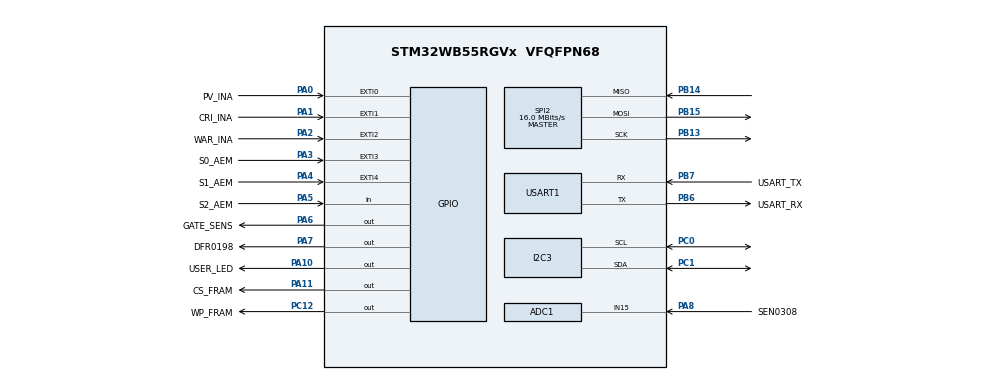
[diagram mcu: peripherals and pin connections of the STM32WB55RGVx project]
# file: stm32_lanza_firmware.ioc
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ADC1.Channel-0\#ChannelRegularConversion=ADC_CHANNEL_15
ADC1.NbrOfConversionFlag=1
ADC1.OffsetNumber-0\#ChannelRegularConversion=ADC_OFFSET_NONE
ADC1.Rank-0\#ChannelRegularConversion=1
ADC1.SamplingTime-0\#ChannelRegularConversion=ADC_SAMPLETIME_47CYCLES_5
ADC1.master=1
I2C3.Timing=0x00B07CB4
Mcu.Family=STM32WB
Mcu.Name=STM32WB55RGVx
Mcu.Package=VFQFPN68
NVIC.EXTI0_IRQn=true\:0\:0\:false\:false\:true\:true\:true\:true
NVIC.EXTI1_IRQn=true\:0\:0\:false\:false\:true\:true\:true\:true
NVIC.EXTI2_IRQn=true\:0\:0\:false\:false\:true\:true\:true\:true
NVIC.EXTI3_IRQn=true\:0\:0\:false\:false\:true\:true\:true\:true
NVIC.EXTI4_IRQn=true\:0\:0\:false\:false\:true\:true\:true\:true
NVIC.PriorityGroup=NVIC_PRIORITYGROUP_4
NVIC.RTC_WKUP_IRQn=true\:0\:0\:false\:false\:true\:true\:true\:true
NVIC.USART1_IRQn=true\:0\:0\:false\:false\:true\:true\:true\:true
OSC_IN.GPIO_Label=RCC_OSC_IN
OSC_IN.Mode=HSE-External-Oscillator
OSC_IN.Signal=RCC_OSC_IN
OSC_OUT.GPIO_Label=RCC_OSC_OUT
OSC_OUT.Mode=HSE-External-Oscillator
OSC_OUT.Signal=RCC_OSC_OUT
PA0.GPIO_Label=PV_INA
PA0.Signal=GPXTI0
PA1.GPIO_Label=CRI_INA
PA1.Signal=GPXTI1
PA10.GPIO_Label=USER_LED
PA10.Signal=GPIO_Output
PA11.GPIO_Label=CS_FRAM
PA11.Signal=GPIO_Output
PA13.Mode=Serial_Wire
PA13.Signal=SYS_JTMS-SWDIO
PA14.Mode=Serial_Wire
PA14.Signal=SYS_JTCK-SWCLK
PA2.GPIO_Label=WAR_INA
PA2.Signal=GPXTI2
PA3.GPIO_Label=S0_AEM
PA3.GPIO_ModeDefaultEXTI=GPIO_MODE_IT_RISING_FALLING
PA3.Signal=GPXTI3
PA4.GPIO_Label=S1_AEM
PA4.Signal=GPXTI4
PA5.GPIO_Label=S2_AEM
PA5.Signal=GPIO_Input
PA6.GPIO_Label=GATE_SENS
PA6.Signal=GPIO_Output
PA7.GPIO_Label=DFR0198
PA7.GPIO_ModeDefaultOutputPP=GPIO_MODE_OUTPUT_OD
PA7.GPIO_PuPd=GPIO_PULLUP
PA7.PinState=GPIO_PIN_SET
PA7.Signal=GPIO_Output
PA8.GPIO_Label=SEN0308
PA8.Signal=ADCx_IN15
PB13.Mode=Full_Duplex_Master
PB13.Signal=SPI2_SCK
PB14.Mode=Full_Duplex_Master
PB14.Signal=SPI2_MISO
PB15.Mode=Full_Duplex_Master
PB15.Signal=SPI2_MOSI
PB6.GPIO_Label=USART_RX
PB6.Mode=Asynchronous
PB6.Signal=USART1_TX
PB7.GPIO_Label=USART_TX
PB7.Mode=Asynchronous
PB7.Signal=USART1_RX
PC0.GPIO_Pu=GPIO_PULLUP
PC0.Mode=I2C
PC0.Signal=I2C3_SCL
PC1.GPIO_Pu=GPIO_PULLUP
PC1.Mode=I2C
PC1.Signal=I2C3_SDA
PC12.GPIO_Label=WP_FRAM
PC12.Signal=GPIO_Output
PC14-OSC32_IN.Mode=LSE-External-Oscillator
PC14-OSC32_IN.Signal=RCC_OSC32_IN
PC15-OSC32_OUT.Mode=LSE-External-Oscillator
PC15-OSC32_OUT.Signal=RCC_OSC32_OUT
ProjectManager.HeapSize=0x200
ProjectManager.StackSize=0x400
ProjectManager.TargetToolchain=STM32CubeIDE
RCC.ADCFreq_Value=64000000
RCC.AHBFreq_Value=32000000
RCC.APB1Freq_Value=32000000
RCC.APB1TimFreq_Value=32000000
RCC.APB2Freq_Value=32000000
RCC.APB2TimFreq_Value=32000000
RCC.APB3Freq_Value=16000000
RCC.CortexFreq_Value=32000000
RCC.HCLKFreq_Value=32000000
RCC.HSE_VALUE=32000000
RCC.HSI48_VALUE=48000000
RCC.HSI_VALUE=16000000
RCC.MSIClockRange=RCC_MSIRANGE_10
RCC.PLLM=RCC_PLLM_DIV2
RCC.RTCClockSelection=RCC_RTCCLKSOURCE_LSE
RCC.SMPSCLockSelection=RCC_SMPSCLKSOURCE_HSI
RCC.SMPSCLockSelectionVirtual=RCC_SMPSCLKSOURCE_HSI
RCC.SMPSCLockSelectionVirtualVirtual=RCC_SMPSCLKSOURCE_HSI
RCC.SMPSDivider=1
RCC.SYSCLKFreq_VALUE=32000000
RCC.USBFreq_Value=64000000
RCC.VCOOutputFreq_Value=128000000
RTC.WakeUpClock-WakeUp=RTC_WAKEUPCLOCK_CK_SPRE_16BITS
RTC.WakeUpCounter-WakeUp=1200
SH.ADCx_IN15.0=ADC1_IN15,IN15-Single-Ended
SPI2.BaudRatePrescaler=SPI_BAUDRATEPRESCALER_2
SPI2.CalculateBaudRate=16.0 MBits/s
SPI2.DataSize=SPI_DATASIZE_8BIT
SPI2.Direction=SPI_DIRECTION_2LINES
SPI2.Mode=SPI_MODE_MASTER
SPI2.VirtualType=VM_MASTER
USART1.AutoBaudRateEnableParam=UART_ADVFEATURE_AUTOBAUDRATE_DISABLE
USART1.VirtualMode-Asynchronous=VM_ASYNC
VP_MEMORYMAP_VS_MEMORYMAP.Mode=CurAppReg
VP_RTC_VS_RTC_Activate.Mode=RTC_Enabled
VP_RTC_VS_RTC_Calendar.Mode=RTC_Calendar
VP_RTC_VS_RTC_WakeUp_intern.Mode=WakeUp
board=NUCLEO-WB55RG

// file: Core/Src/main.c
/* USER CODE BEGIN Header */
/**
  ******************************************************************************
  * @file           : main.c
  * @brief          : Main program body
  ******************************************************************************
  * @attention
  *
  * Copyright (c) 2025 STMicroelectronics.
  * All rights reserved.
  *
  * This software is licensed under terms that can be found in the LICENSE file
  * in the root directory of this software component.
  * If no LICENSE file comes with this software, it is provided AS-IS.
  *
  ******************************************************************************
  */
/* USER CODE END Header */
#include "main.h"

/* USER CODE BEGIN Includes */
#include "app.h"
/* USER CODE END Includes */

ADC_HandleTypeDef hadc1;

I2C_HandleTypeDef hi2c3;

RTC_HandleTypeDef hrtc;

SPI_HandleTypeDef hspi2;

UART_HandleTypeDef huart1;

void SystemClock_Config(void);
void PeriphCommonClock_Config(void);
static void MX_GPIO_Init(void);
static void MX_USART1_UART_Init(void);
static void MX_RTC_Init(void);
static void MX_ADC1_Init(void);
static void MX_I2C3_Init(void);
static void MX_SPI2_Init(void);
/* USER CODE BEGIN PFP */
void ADC1_Init() {
	HAL_ADC_DeInit(&hadc1);
	HAL_ADC_Init(&hadc1);

	MX_ADC1_Init();
}
/* USER CODE END PFP */

/* USER CODE BEGIN 0 */

// Overwritten function to allow printf() via UART
int _write(int file, char *ptr, int len) {
    HAL_UART_Transmit(&huart1, (uint8_t*)ptr, len, HAL_MAX_DELAY);
    return len;
}
/* USER CODE END 0 */

int main(void)
{

  /* MCU Configuration--------------------------------------------------------*/

  /* Reset of all peripherals, Initializes the Flash interface and the Systick. */
  HAL_Init();

  /* Configure the system clock */
  SystemClock_Config();

  /* Configure the peripherals common clocks */
  PeriphCommonClock_Config();

  /* Initialize all configured peripherals */
  MX_GPIO_Init();
  MX_USART1_UART_Init();
  MX_RTC_Init();
  MX_ADC1_Init();
  MX_I2C3_Init();
  MX_SPI2_Init();
  /* USER CODE BEGIN 2 */
  setup();
  /* USER CODE END 2 */

  /* Infinite loop */
  while (1)
  {

    /* USER CODE BEGIN 3 */
	  loop();
  }
  /* USER CODE END 3 */
}

void SystemClock_Config(void)
{
  RCC_OscInitTypeDef RCC_OscInitStruct = {0};
  RCC_ClkInitTypeDef RCC_ClkInitStruct = {0};

  /** Macro to configure the PLL multiplication factor
  */
  __HAL_RCC_PLL_PLLM_CONFIG(RCC_PLLM_DIV2);

  /** Macro to configure the PLL clock source
  */
  __HAL_RCC_PLL_PLLSOURCE_CONFIG(RCC_PLLSOURCE_MSI);

  /** Configure LSE Drive Capability
  */
  HAL_PWR_EnableBkUpAccess();
  __HAL_RCC_LSEDRIVE_CONFIG(RCC_LSEDRIVE_MEDIUMHIGH);

  /** Configure the main internal regulator output voltage
  */
  __HAL_PWR_VOLTAGESCALING_CONFIG(PWR_REGULATOR_VOLTAGE_SCALE1);

  /** Initializes the RCC Oscillators according to the specified parameters
  * in the RCC_OscInitTypeDef structure.
  */
  RCC_OscInitStruct.OscillatorType = RCC_OSCILLATORTYPE_HSI|RCC_OSCILLATORTYPE_HSE
                              |RCC_OSCILLATORTYPE_LSE|RCC_OSCILLATORTYPE_MSI;
  RCC_OscInitStruct.HSEState = RCC_HSE_ON;
  RCC_OscInitStruct.LSEState = RCC_LSE_ON;
  RCC_OscInitStruct.HSIState = RCC_HSI_ON;
  RCC_OscInitStruct.MSIState = RCC_MSI_ON;
  RCC_OscInitStruct.HSICalibrationValue = RCC_HSICALIBRATION_DEFAULT;
  RCC_OscInitStruct.MSICalibrationValue = RCC_MSICALIBRATION_DEFAULT;
  RCC_OscInitStruct.MSIClockRange = RCC_MSIRANGE_10;
  RCC_OscInitStruct.PLL.PLLState = RCC_PLL_NONE;
  if (HAL_RCC_OscConfig(&RCC_OscInitStruct) != HAL_OK)
  {
    Error_Handler();
  }

  /** Configure the SYSCLKSource, HCLK, PCLK1 and PCLK2 clocks dividers
  */
  RCC_ClkInitStruct.ClockType = RCC_CLOCKTYPE_HCLK4|RCC_CLOCKTYPE_HCLK2
                              |RCC_CLOCKTYPE_HCLK|RCC_CLOCKTYPE_SYSCLK
                              |RCC_CLOCKTYPE_PCLK1|RCC_CLOCKTYPE_PCLK2;
  RCC_ClkInitStruct.SYSCLKSource = RCC_SYSCLKSOURCE_MSI;
  RCC_ClkInitStruct.AHBCLKDivider = RCC_SYSCLK_DIV1;
  RCC_ClkInitStruct.APB1CLKDivider = RCC_HCLK_DIV1;
  RCC_ClkInitStruct.APB2CLKDivider = RCC_HCLK_DIV1;
  RCC_ClkInitStruct.AHBCLK2Divider = RCC_SYSCLK_DIV1;
  RCC_ClkInitStruct.AHBCLK4Divider = RCC_SYSCLK_DIV1;

  if (HAL_RCC_ClockConfig(&RCC_ClkInitStruct, FLASH_LATENCY_1) != HAL_OK)
  {
    Error_Handler();
  }
}

void PeriphCommonClock_Config(void)
{
  RCC_PeriphCLKInitTypeDef PeriphClkInitStruct = {0};

  /** Initializes the peripherals clock
  */
  PeriphClkInitStruct.PeriphClockSelection = RCC_PERIPHCLK_SMPS;
  PeriphClkInitStruct.SmpsClockSelection = RCC_SMPSCLKSOURCE_HSI;
  PeriphClkInitStruct.SmpsDivSelection = RCC_SMPSCLKDIV_RANGE0;

  if (HAL_RCCEx_PeriphCLKConfig(&PeriphClkInitStruct) != HAL_OK)
  {
    Error_Handler();
  }
}

static void MX_ADC1_Init(void)
{

  ADC_ChannelConfTypeDef sConfig = {0};

  /** Common config
  */
  hadc1.Instance = ADC1;
  hadc1.Init.ClockPrescaler = ADC_CLOCK_ASYNC_DIV1;
  hadc1.Init.Resolution = ADC_RESOLUTION_12B;
  hadc1.Init.DataAlign = ADC_DATAALIGN_RIGHT;
  hadc1.Init.ScanConvMode = ADC_SCAN_DISABLE;
  hadc1.Init.EOCSelection = ADC_EOC_SINGLE_CONV;
  hadc1.Init.LowPowerAutoWait = DISABLE;
  hadc1.Init.ContinuousConvMode = DISABLE;
  hadc1.Init.NbrOfConversion = 1;
  hadc1.Init.DiscontinuousConvMode = DISABLE;
  hadc1.Init.ExternalTrigConv = ADC_SOFTWARE_START;
  hadc1.Init.ExternalTrigConvEdge = ADC_EXTERNALTRIGCONVEDGE_NONE;
  hadc1.Init.DMAContinuousRequests = DISABLE;
  hadc1.Init.Overrun = ADC_OVR_DATA_PRESERVED;
  hadc1.Init.OversamplingMode = DISABLE;
  if (HAL_ADC_Init(&hadc1) != HAL_OK)
  {
    Error_Handler();
  }

  /** Configure Regular Channel
  */
  sConfig.Channel = ADC_CHANNEL_15;
  sConfig.Rank = ADC_REGULAR_RANK_1;
  sConfig.SamplingTime = ADC_SAMPLETIME_47CYCLES_5;
  sConfig.SingleDiff = ADC_SINGLE_ENDED;
  sConfig.OffsetNumber = ADC_OFFSET_NONE;
  sConfig.Offset = 0;
  if (HAL_ADC_ConfigChannel(&hadc1, &sConfig) != HAL_OK)
  {
    Error_Handler();
  }

}

static void MX_I2C3_Init(void)
{

  hi2c3.Instance = I2C3;
  hi2c3.Init.Timing = 0x00B07CB4;
  hi2c3.Init.OwnAddress1 = 0;
  hi2c3.Init.AddressingMode = I2C_ADDRESSINGMODE_7BIT;
  hi2c3.Init.DualAddressMode = I2C_DUALADDRESS_DISABLE;
  hi2c3.Init.OwnAddress2 = 0;
  hi2c3.Init.OwnAddress2Masks = I2C_OA2_NOMASK;
  hi2c3.Init.GeneralCallMode = I2C_GENERALCALL_DISABLE;
  hi2c3.Init.NoStretchMode = I2C_NOSTRETCH_DISABLE;
  if (HAL_I2C_Init(&hi2c3) != HAL_OK)
  {
    Error_Handler();
  }

  /** Configure Analogue filter
  */
  if (HAL_I2CEx_ConfigAnalogFilter(&hi2c3, I2C_ANALOGFILTER_ENABLE) != HAL_OK)
  {
    Error_Handler();
  }

  /** Configure Digital filter
  */
  if (HAL_I2CEx_ConfigDigitalFilter(&hi2c3, 0) != HAL_OK)
  {
    Error_Handler();
  }

}

static void MX_RTC_Init(void)
{

  RTC_TimeTypeDef sTime = {0};
  RTC_DateTypeDef sDate = {0};

  /** Initialize RTC Only
  */
  hrtc.Instance = RTC;
  hrtc.Init.HourFormat = RTC_HOURFORMAT_24;
  hrtc.Init.AsynchPrediv = 127;
  hrtc.Init.SynchPrediv = 255;
  hrtc.Init.OutPut = RTC_OUTPUT_DISABLE;
  hrtc.Init.OutPutPolarity = RTC_OUTPUT_POLARITY_HIGH;
  hrtc.Init.OutPutType = RTC_OUTPUT_TYPE_OPENDRAIN;
  hrtc.Init.OutPutRemap = RTC_OUTPUT_REMAP_NONE;
  if (HAL_RTC_Init(&hrtc) != HAL_OK)
  {
    Error_Handler();
  }

  /** Initialize RTC and set the Time and Date
  */
  sTime.Hours = 0x0;
  sTime.Minutes = 0x0;
  sTime.Seconds = 0x0;
  sTime.SubSeconds = 0x0;
  sTime.DayLightSaving = RTC_DAYLIGHTSAVING_NONE;
  sTime.StoreOperation = RTC_STOREOPERATION_RESET;
  if (HAL_RTC_SetTime(&hrtc, &sTime, RTC_FORMAT_BCD) != HAL_OK)
  {
    Error_Handler();
  }
  sDate.WeekDay = RTC_WEEKDAY_MONDAY;
  sDate.Month = RTC_MONTH_JANUARY;
  sDate.Date = 0x1;
  sDate.Year = 0x0;

  if (HAL_RTC_SetDate(&hrtc, &sDate, RTC_FORMAT_BCD) != HAL_OK)
  {
    Error_Handler();
  }

  /** Enable the WakeUp
  */
  if (HAL_RTCEx_SetWakeUpTimer_IT(&hrtc, 1200, RTC_WAKEUPCLOCK_CK_SPRE_16BITS) != HAL_OK)
  {
    Error_Handler();
  }

}

static void MX_SPI2_Init(void)
{

  /* SPI2 parameter configuration*/
  hspi2.Instance = SPI2;
  hspi2.Init.Mode = SPI_MODE_MASTER;
  hspi2.Init.Direction = SPI_DIRECTION_2LINES;
  hspi2.Init.DataSize = SPI_DATASIZE_8BIT;
  hspi2.Init.CLKPolarity = SPI_POLARITY_LOW;
  hspi2.Init.CLKPhase = SPI_PHASE_1EDGE;
  hspi2.Init.NSS = SPI_NSS_SOFT;
  hspi2.Init.BaudRatePrescaler = SPI_BAUDRATEPRESCALER_2;
  hspi2.Init.FirstBit = SPI_FIRSTBIT_MSB;
  hspi2.Init.TIMode = SPI_TIMODE_DISABLE;
  hspi2.Init.CRCCalculation = SPI_CRCCALCULATION_DISABLE;
  hspi2.Init.CRCPolynomial = 7;
  hspi2.Init.CRCLength = SPI_CRC_LENGTH_DATASIZE;
  hspi2.Init.NSSPMode = SPI_NSS_PULSE_ENABLE;
  if (HAL_SPI_Init(&hspi2) != HAL_OK)
  {
    Error_Handler();
  }

}

static void MX_USART1_UART_Init(void)
{

  huart1.Instance = USART1;
  huart1.Init.BaudRate = 115200;
  huart1.Init.WordLength = UART_WORDLENGTH_8B;
  huart1.Init.StopBits = UART_STOPBITS_1;
  huart1.Init.Parity = UART_PARITY_NONE;
  huart1.Init.Mode = UART_MODE_TX_RX;
  huart1.Init.HwFlowCtl = UART_HWCONTROL_NONE;
  huart1.Init.OverSampling = UART_OVERSAMPLING_16;
  huart1.Init.OneBitSampling = UART_ONE_BIT_SAMPLE_DISABLE;
  huart1.Init.ClockPrescaler = UART_PRESCALER_DIV1;
  huart1.AdvancedInit.AdvFeatureInit = UART_ADVFEATURE_NO_INIT;
  if (HAL_UART_Init(&huart1) != HAL_OK)
  {
    Error_Handler();
  }
  if (HAL_UARTEx_SetTxFifoThreshold(&huart1, UART_TXFIFO_THRESHOLD_1_8) != HAL_OK)
  {
    Error_Handler();
  }
  if (HAL_UARTEx_SetRxFifoThreshold(&huart1, UART_RXFIFO_THRESHOLD_1_8) != HAL_OK)
  {
    Error_Handler();
  }
  if (HAL_UARTEx_DisableFifoMode(&huart1) != HAL_OK)
  {
    Error_Handler();
  }

}

static void MX_GPIO_Init(void)
{
  GPIO_InitTypeDef GPIO_InitStruct = {0};

  /* GPIO Ports Clock Enable */
  __HAL_RCC_GPIOC_CLK_ENABLE();
  __HAL_RCC_GPIOA_CLK_ENABLE();
  __HAL_RCC_GPIOB_CLK_ENABLE();

  /*Configure GPIO pin Output Level */
  HAL_GPIO_WritePin(GPIOA, GATE_SENS_Pin|USER_LED_Pin|CS_FRAM_Pin, GPIO_PIN_RESET);

  /*Configure GPIO pin Output Level */
  HAL_GPIO_WritePin(DFR0198_GPIO_Port, DFR0198_Pin, GPIO_PIN_SET);

  /*Configure GPIO pin Output Level */
  HAL_GPIO_WritePin(WP_FRAM_GPIO_Port, WP_FRAM_Pin, GPIO_PIN_RESET);

  /*Configure GPIO pins : PV_INA_Pin CRI_INA_Pin WAR_INA_Pin S1_AEM_Pin */
  GPIO_InitStruct.Pin = PV_INA_Pin|CRI_INA_Pin|WAR_INA_Pin|S1_AEM_Pin;
  GPIO_InitStruct.Mode = GPIO_MODE_IT_RISING;
  GPIO_InitStruct.Pull = GPIO_NOPULL;
  HAL_GPIO_Init(GPIOA, &GPIO_InitStruct);

  /*Configure GPIO pin : S0_AEM_Pin */
  GPIO_InitStruct.Pin = S0_AEM_Pin;
  GPIO_InitStruct.Mode = GPIO_MODE_IT_RISING_FALLING;
  GPIO_InitStruct.Pull = GPIO_NOPULL;
  HAL_GPIO_Init(S0_AEM_GPIO_Port, &GPIO_InitStruct);

  /*Configure GPIO pin : S2_AEM_Pin */
  GPIO_InitStruct.Pin = S2_AEM_Pin;
  GPIO_InitStruct.Mode = GPIO_MODE_INPUT;
  GPIO_InitStruct.Pull = GPIO_NOPULL;
  HAL_GPIO_Init(S2_AEM_GPIO_Port, &GPIO_InitStruct);

  /*Configure GPIO pins : GATE_SENS_Pin USER_LED_Pin CS_FRAM_Pin */
  GPIO_InitStruct.Pin = GATE_SENS_Pin|USER_LED_Pin|CS_FRAM_Pin;
  GPIO_InitStruct.Mode = GPIO_MODE_OUTPUT_PP;
  GPIO_InitStruct.Pull = GPIO_NOPULL;
  GPIO_InitStruct.Speed = GPIO_SPEED_FREQ_LOW;
  HAL_GPIO_Init(GPIOA, &GPIO_InitStruct);

  /*Configure GPIO pin : DFR0198_Pin */
  GPIO_InitStruct.Pin = DFR0198_Pin;
  GPIO_InitStruct.Mode = GPIO_MODE_OUTPUT_OD;
  GPIO_InitStruct.Pull = GPIO_PULLUP;
  GPIO_InitStruct.Speed = GPIO_SPEED_FREQ_LOW;
  HAL_GPIO_Init(DFR0198_GPIO_Port, &GPIO_InitStruct);

  /*Configure GPIO pin : WP_FRAM_Pin */
  GPIO_InitStruct.Pin = WP_FRAM_Pin;
  GPIO_InitStruct.Mode = GPIO_MODE_OUTPUT_PP;
  GPIO_InitStruct.Pull = GPIO_NOPULL;
  GPIO_InitStruct.Speed = GPIO_SPEED_FREQ_LOW;
  HAL_GPIO_Init(WP_FRAM_GPIO_Port, &GPIO_InitStruct);

  /* EXTI interrupt init*/
  HAL_NVIC_SetPriority(EXTI0_IRQn, 0, 0);
  HAL_NVIC_EnableIRQ(EXTI0_IRQn);

  HAL_NVIC_SetPriority(EXTI1_IRQn, 0, 0);
  HAL_NVIC_EnableIRQ(EXTI1_IRQn);

  HAL_NVIC_SetPriority(EXTI2_IRQn, 0, 0);
  HAL_NVIC_EnableIRQ(EXTI2_IRQn);

  HAL_NVIC_SetPriority(EXTI3_IRQn, 0, 0);
  HAL_NVIC_EnableIRQ(EXTI3_IRQn);

  HAL_NVIC_SetPriority(EXTI4_IRQn, 0, 0);
  HAL_NVIC_EnableIRQ(EXTI4_IRQn);

}

void Error_Handler(void)
{
  __disable_irq();
  while (1)
  {
  }
}
